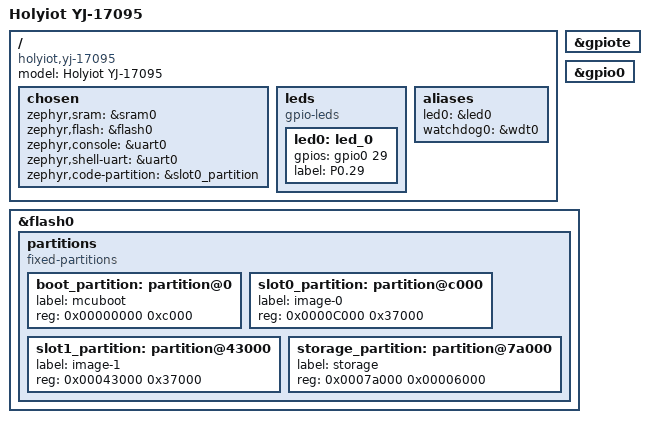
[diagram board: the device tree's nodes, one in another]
/*
 * Copyright (c) 2025 Marc Lasch <mlasch@mailbox.org>
 *
 * SPDX-License-Identifier: Apache-2.0
 */

/dts-v1/;
#include <nordic/nrf52832_qfaa.dtsi>

/ {
	model = "Holyiot YJ-17095";
	compatible = "holyiot,yj-17095";

	chosen {
		zephyr,sram = &sram0;
		zephyr,flash = &flash0;
		zephyr,console = &uart0;
		zephyr,shell-uart = &uart0;
		zephyr,code-partition = &slot0_partition;
	};

	leds {
		compatible = "gpio-leds";

		led0: led_0 {
			gpios = <&gpio0 29 GPIO_ACTIVE_HIGH>;
			label = "P0.29";
		};
	};

	/* These aliases are provided for compatibility with samples */
	aliases {
		led0 = &led0;
		watchdog0 = &wdt0;
	};
};

&gpiote {
	status = "okay";
};

&gpio0 {
	status = "okay";
};

&flash0 {
	partitions {
		compatible = "fixed-partitions";
		#address-cells = <1>;
		#size-cells = <1>;

		boot_partition: partition@0 {
			label = "mcuboot";
			reg = <0x00000000 0xc000>;
		};

		slot0_partition: partition@c000 {
			label = "image-0";
			reg = <0x0000C000 0x37000>;
		};

		slot1_partition: partition@43000 {
			label = "image-1";
			reg = <0x00043000 0x37000>;
		};

		storage_partition: partition@7a000 {
			label = "storage";
			reg = <0x0007a000 0x00006000>;
		};
	};
};
